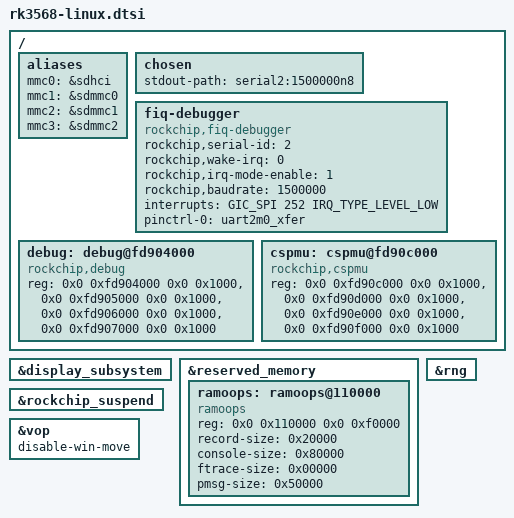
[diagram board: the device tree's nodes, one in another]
// SPDX-License-Identifier: (GPL-2.0+ OR MIT)
/*
 * Copyright (c) 2020 Rockchip Electronics Co., Ltd.
 *
 */

/ {
	aliases {
		mmc0 = &sdhci;
		mmc1 = &sdmmc0;
		mmc2 = &sdmmc1;
		mmc3 = &sdmmc2;
	};

	chosen: chosen {
		stdout-path = "serial2:1500000n8";
	};

	fiq-debugger {
		compatible = "rockchip,fiq-debugger";
		rockchip,serial-id = <2>;
		rockchip,wake-irq = <0>;
		/* If enable uart uses irq instead of fiq */
		rockchip,irq-mode-enable = <1>;
		rockchip,baudrate = <1500000>;  /* Only 115200 and 1500000 */
		interrupts = <GIC_SPI 252 IRQ_TYPE_LEVEL_LOW>;
		pinctrl-names = "default";
		pinctrl-0 = <&uart2m0_xfer>;
		status = "okay";
	};

	debug: debug@fd904000 {
		compatible = "rockchip,debug";
		reg = <0x0 0xfd904000 0x0 0x1000>,
			<0x0 0xfd905000 0x0 0x1000>,
			<0x0 0xfd906000 0x0 0x1000>,
			<0x0 0xfd907000 0x0 0x1000>;
	};

	cspmu: cspmu@fd90c000 {
		compatible = "rockchip,cspmu";
		reg = <0x0 0xfd90c000 0x0 0x1000>,
			<0x0 0xfd90d000 0x0 0x1000>,
			<0x0 0xfd90e000 0x0 0x1000>,
			<0x0 0xfd90f000 0x0 0x1000>;
	};
};

/*
 * drm-logo@0 and drm-cubic-lut@0 are placeholders for a splash
 * framebuffer region that downstream Rockchip U-Boot patches at
 * handoff. Armbian uses a generic U-Boot that never fills these,
 * so the reservation fails with "base 0x0, size 0 MiB" and the
 * DRM driver logs "failed to parse loader memory". Drop both the
 * phandle references in display-subsystem and the placeholder
 * nodes themselves so the bootlog stays clean; boot logo is drawn
 * by plymouth after init instead.
 */
&display_subsystem {
	/delete-property/ memory-region;
	/delete-property/ memory-region-names;
};

&reserved_memory {
	/delete-node/ drm-logo@0;
	/delete-node/ drm-cubic-lut@0;

	ramoops: ramoops@110000 {
		compatible = "ramoops";
		reg = <0x0 0x110000 0x0 0xf0000>;
		record-size = <0x20000>;
		console-size = <0x80000>;
		ftrace-size = <0x00000>;
		pmsg-size = <0x50000>;
	};
};

&rng {
	status = "okay";
};

&rockchip_suspend {
	status = "okay";
};

&vop {
	disable-win-move;
};
